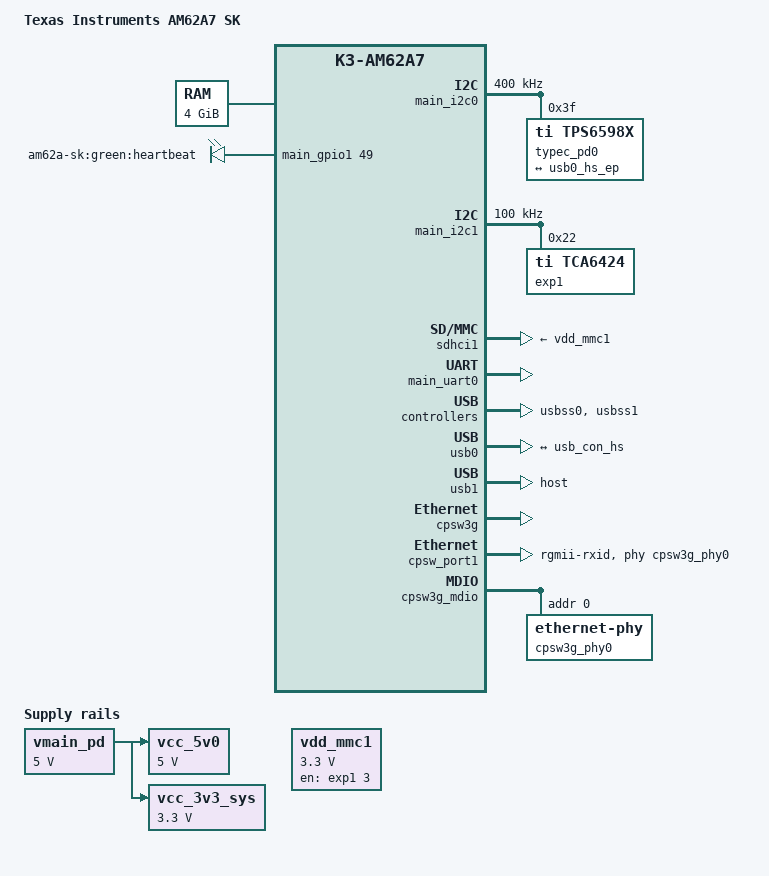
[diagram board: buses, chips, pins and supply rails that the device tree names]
/dts-v1/;
#include <dt-bindings/leds/common.h>
#include <dt-bindings/gpio/gpio.h>
#include <dt-bindings/net/ti-dp83867.h>
#include "k3-am62a7.dtsi"
/ {
	compatible = "ti,am62a7-sk", "ti,am62a7";
	model = "Texas Instruments AM62A7 SK";
	aliases {
		serial0 = &wkup_uart0;
		serial2 = &main_uart0;
		serial3 = &main_uart1;
		mmc1 = &sdhci1;
	};
	chosen {
		stdout-path = "serial2:115200n8";
	};
	memory@80000000 {
		device_type = "memory";
		reg = <0x00000000 0x80000000 0x00000000 0x80000000>,
		      <0x00000008 0x80000000 0x00000000 0x80000000>;
	};
	reserved-memory {
		#address-cells = <2>;
		#size-cells = <2>;
		ranges;
		secure_tfa_ddr: tfa@9e780000 {
			reg = <0x00 0x9e780000 0x00 0x80000>;
			alignment = <0x1000>;
			no-map;
		};
		secure_ddr: optee@9e800000 {
			reg = <0x00 0x9e800000 0x00 0x01800000>;  
			alignment = <0x1000>;
			no-map;
		};
		wkup_r5fss0_core0_memory_region: r5f-dma-memory@9c900000 {
			compatible = "shared-dma-pool";
			reg = <0x00 0x9c900000 0x00 0x01e00000>;
			no-map;
		};
	};
	vmain_pd: regulator-0 {
		compatible = "regulator-fixed";
		regulator-name = "vmain_pd";
		regulator-min-microvolt = <5000000>;
		regulator-max-microvolt = <5000000>;
		regulator-always-on;
		regulator-boot-on;
	};
	vcc_5v0: regulator-1 {
		compatible = "regulator-fixed";
		regulator-name = "vcc_5v0";
		regulator-min-microvolt = <5000000>;
		regulator-max-microvolt = <5000000>;
		vin-supply = <&vmain_pd>;
		regulator-always-on;
		regulator-boot-on;
	};
	vcc_3v3_sys: regulator-2 {
		compatible = "regulator-fixed";
		regulator-name = "vcc_3v3_sys";
		regulator-min-microvolt = <3300000>;
		regulator-max-microvolt = <3300000>;
		vin-supply = <&vmain_pd>;
		regulator-always-on;
		regulator-boot-on;
	};
	vdd_mmc1: regulator-3 {
		compatible = "regulator-fixed";
		regulator-name = "vdd_mmc1";
		regulator-min-microvolt = <3300000>;
		regulator-max-microvolt = <3300000>;
		regulator-boot-on;
		enable-active-high;
		gpio = <&exp1 3 GPIO_ACTIVE_HIGH>;
	};
	leds {
		compatible = "gpio-leds";
		pinctrl-names = "default";
		pinctrl-0 = <&usr_led_pins_default>;
		led-0 {
			label = "am62a-sk:green:heartbeat";
			gpios = <&main_gpio1 49 GPIO_ACTIVE_HIGH>;
			linux,default-trigger = "heartbeat";
			function = LED_FUNCTION_HEARTBEAT;
			default-state = "off";
		};
	};
};
&mcu_pmx0 {
	wkup_uart0_pins_default: wkup-uart0-default-pins {
		pinctrl-single,pins = <
			AM62AX_MCU_IOPAD(0x0024, PIN_INPUT, 0)  
			AM62AX_MCU_IOPAD(0x0028, PIN_OUTPUT, 0)  
			AM62AX_MCU_IOPAD(0x002c, PIN_INPUT, 0)  
			AM62AX_MCU_IOPAD(0x0030, PIN_OUTPUT, 0)  
		>;
	};
};
&wkup_uart0 {
	pinctrl-names = "default";
	pinctrl-0 = <&wkup_uart0_pins_default>;
	status = "reserved";
};
&main_pmx0 {
	main_uart0_pins_default: main-uart0-default-pins {
		pinctrl-single,pins = <
			AM62AX_IOPAD(0x1c8, PIN_INPUT, 0)  
			AM62AX_IOPAD(0x1cc, PIN_OUTPUT, 0)  
		>;
	};
	main_uart1_pins_default: main-uart1-default-pins {
		pinctrl-single,pins = <
			AM62AX_IOPAD(0x01e8, PIN_INPUT, 1)  
			AM62AX_IOPAD(0x01ec, PIN_OUTPUT, 1)  
			AM62AX_IOPAD(0x0194, PIN_INPUT, 2)  
			AM62AX_IOPAD(0x0198, PIN_OUTPUT, 2)  
		>;
	};
	main_i2c0_pins_default: main-i2c0-default-pins {
		pinctrl-single,pins = <
			AM62AX_IOPAD(0x1e0, PIN_INPUT_PULLUP, 0)  
			AM62AX_IOPAD(0x1e4, PIN_INPUT_PULLUP, 0)  
		>;
	};
	main_i2c1_pins_default: main-i2c1-default-pins {
		pinctrl-single,pins = <
			AM62AX_IOPAD(0x1e8, PIN_INPUT_PULLUP, 0)  
			AM62AX_IOPAD(0x1ec, PIN_INPUT_PULLUP, 0)  
		>;
	};
	main_i2c2_pins_default: main-i2c2-default-pins {
		pinctrl-single,pins = <
			AM62AX_IOPAD(0x0b0, PIN_INPUT_PULLUP, 1)  
			AM62AX_IOPAD(0x0b4, PIN_INPUT_PULLUP, 1)  
		>;
	};
	main_mmc1_pins_default: main-mmc1-default-pins {
		pinctrl-single,pins = <
			AM62AX_IOPAD(0x23c, PIN_INPUT, 0)  
			AM62AX_IOPAD(0x234, PIN_INPUT, 0)  
			AM62AX_IOPAD(0x230, PIN_INPUT, 0)  
			AM62AX_IOPAD(0x22c, PIN_INPUT, 0)  
			AM62AX_IOPAD(0x228, PIN_INPUT, 0)  
			AM62AX_IOPAD(0x224, PIN_INPUT, 0)  
			AM62AX_IOPAD(0x240, PIN_INPUT, 0)  
		>;
	};
	usr_led_pins_default: usr-led-default-pins {
		pinctrl-single,pins = <
			AM62AX_IOPAD(0x244, PIN_OUTPUT, 7)  
		>;
	};
	main_usb1_pins_default: main-usb1-default-pins {
		pinctrl-single,pins = <
			AM62AX_IOPAD(0x0258, PIN_OUTPUT, 0)  
		>;
	};
	main_mdio1_pins_default: main-mdio1-default-pins {
		pinctrl-single,pins = <
			AM62AX_IOPAD(0x160, PIN_OUTPUT, 0)  
			AM62AX_IOPAD(0x15c, PIN_INPUT, 0)  
		>;
	};
	main_rgmii1_pins_default: main-rgmii1-default-pins {
		pinctrl-single,pins = <
			AM62AX_IOPAD(0x14c, PIN_INPUT, 0)  
			AM62AX_IOPAD(0x150, PIN_INPUT, 0)  
			AM62AX_IOPAD(0x154, PIN_INPUT, 0)  
			AM62AX_IOPAD(0x158, PIN_INPUT, 0)  
			AM62AX_IOPAD(0x148, PIN_INPUT, 0)  
			AM62AX_IOPAD(0x144, PIN_INPUT, 0)  
			AM62AX_IOPAD(0x134, PIN_INPUT, 0)  
			AM62AX_IOPAD(0x138, PIN_INPUT, 0)  
			AM62AX_IOPAD(0x13c, PIN_INPUT, 0)  
			AM62AX_IOPAD(0x140, PIN_INPUT, 0)  
			AM62AX_IOPAD(0x130, PIN_INPUT, 0)  
			AM62AX_IOPAD(0x12c, PIN_INPUT, 0)  
		>;
	};
};
&main_i2c0 {
	status = "okay";
	pinctrl-names = "default";
	pinctrl-0 = <&main_i2c0_pins_default>;
	clock-frequency = <400000>;
	typec_pd0: usb-power-controller@3f {
		compatible = "ti,tps6598x";
		reg = <0x3f>;
		connector {
			compatible = "usb-c-connector";
			label = "USB-C";
			self-powered;
			data-role = "dual";
			power-role = "sink";
			port {
				usb_con_hs: endpoint {
					remote-endpoint = <&usb0_hs_ep>;
				};
			};
		};
	};
};
&main_i2c1 {
	status = "okay";
	pinctrl-names = "default";
	pinctrl-0 = <&main_i2c1_pins_default>;
	clock-frequency = <100000>;
	exp1: gpio@22 {
		compatible = "ti,tca6424";
		reg = <0x22>;
		gpio-controller;
		#gpio-cells = <2>;
		gpio-line-names = "GPIO_CPSW2_RST", "GPIO_CPSW1_RST",
				   "BT_EN_SOC", "MMC1_SD_EN",
				   "VPP_EN", "EXP_PS_3V3_En",
				   "EXP_PS_5V0_En", "EXP_HAT_DETECT",
				   "GPIO_AUD_RSTn", "GPIO_eMMC_RSTn",
				   "UART1_FET_BUF_EN", "BT_UART_WAKE_SOC",
				   "GPIO_HDMI_RSTn", "CSI_GPIO0",
				   "CSI_GPIO1", "WLAN_ALERTn",
				   "HDMI_INTn", "TEST_GPIO2",
				   "MCASP1_FET_EN", "MCASP1_BUF_BT_EN",
				   "MCASP1_FET_SEL", "UART1_FET_SEL",
				   "PD_I2C_IRQ", "IO_EXP_TEST_LED";
	};
};
&sdhci1 {
	status = "okay";
	vmmc-supply = <&vdd_mmc1>;
	pinctrl-names = "default";
	pinctrl-0 = <&main_mmc1_pins_default>;
	ti,driver-strength-ohm = <50>;
	disable-wp;
};
&main_gpio0 {
	status = "okay";
};
&main_gpio1 {
	status = "okay";
};
&main_gpio_intr {
	status = "okay";
};
&main_uart0 {
	status = "okay";
	pinctrl-names = "default";
	pinctrl-0 = <&main_uart0_pins_default>;
};
&main_uart1 {
	pinctrl-names = "default";
	pinctrl-0 = <&main_uart1_pins_default>;
	status = "reserved";
};
&usbss0 {
	status = "okay";
	ti,vbus-divider;
};
&usb0 {
	usb-role-switch;
	port {
		usb0_hs_ep: endpoint {
			remote-endpoint = <&usb_con_hs>;
		};
	};
};
&usbss1 {
	status = "okay";
};
&usb1 {
	dr_mode = "host";
	pinctrl-names = "default";
	pinctrl-0 = <&main_usb1_pins_default>;
};
&cpsw3g {
	status = "okay";
	pinctrl-names = "default";
	pinctrl-0 = <&main_rgmii1_pins_default>;
};
&cpsw_port1 {
	status = "okay";
	phy-mode = "rgmii-rxid";
	phy-handle = <&cpsw3g_phy0>;
};
&cpsw_port2 {
	status = "disabled";
};
&cpsw3g_mdio {
	status = "okay";
	pinctrl-names = "default";
	pinctrl-0 = <&main_mdio1_pins_default>;
	cpsw3g_phy0: ethernet-phy@0 {
		reg = <0>;
		ti,rx-internal-delay = <DP83867_RGMIIDCTL_2_00_NS>;
		ti,fifo-depth = <DP83867_PHYCR_FIFO_DEPTH_4_B_NIB>;
		ti,min-output-impedance;
	};
};
